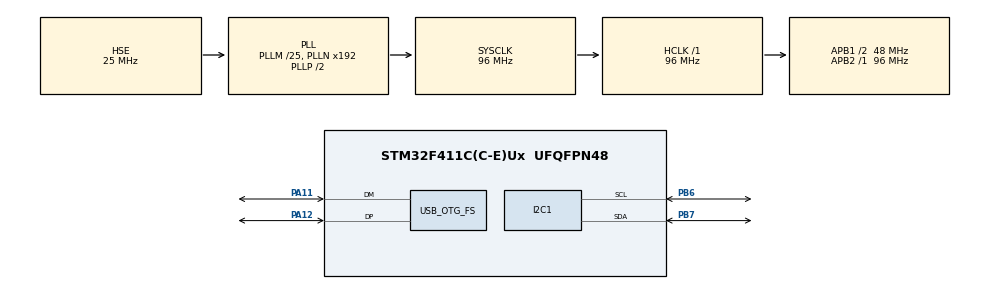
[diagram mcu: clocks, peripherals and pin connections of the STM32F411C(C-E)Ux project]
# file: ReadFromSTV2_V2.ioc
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Dma.I2C1_RX.0.Direction=DMA_PERIPH_TO_MEMORY
Dma.I2C1_RX.0.FIFOMode=DMA_FIFOMODE_DISABLE
Dma.I2C1_RX.0.Instance=DMA1_Stream0
Dma.I2C1_RX.0.MemDataAlignment=DMA_MDATAALIGN_BYTE
Dma.I2C1_RX.0.MemInc=DMA_MINC_ENABLE
Dma.I2C1_RX.0.Mode=DMA_NORMAL
Dma.I2C1_RX.0.PeriphDataAlignment=DMA_PDATAALIGN_BYTE
Dma.I2C1_RX.0.PeriphInc=DMA_PINC_DISABLE
Dma.I2C1_RX.0.Priority=DMA_PRIORITY_LOW
Dma.Request0=I2C1_RX
Mcu.Family=STM32F4
Mcu.Name=STM32F411C(C-E)Ux
Mcu.Package=UFQFPN48
NVIC.DMA1_Stream0_IRQn=true\:0\:0\:false\:false\:true\:false\:true\:true
NVIC.I2C1_ER_IRQn=true\:0\:0\:false\:false\:true\:true\:true\:true
NVIC.I2C1_EV_IRQn=true\:0\:0\:false\:false\:true\:true\:true\:true
NVIC.OTG_FS_IRQn=true\:0\:0\:false\:false\:true\:false\:true\:true
NVIC.PriorityGroup=NVIC_PRIORITYGROUP_4
NVIC.TIM2_IRQn=true\:0\:0\:false\:false\:true\:true\:true\:true
PA11.Mode=Device_Only
PA11.Signal=USB_OTG_FS_DM
PA12.Mode=Device_Only
PA12.Signal=USB_OTG_FS_DP
PB6.Mode=I2C
PB6.Signal=I2C1_SCL
PB7.Mode=I2C
PB7.Signal=I2C1_SDA
PH0\ -\ OSC_IN.Mode=HSE-External-Oscillator
PH0\ -\ OSC_IN.Signal=RCC_OSC_IN
PH1\ -\ OSC_OUT.Mode=HSE-External-Oscillator
PH1\ -\ OSC_OUT.Signal=RCC_OSC_OUT
ProjectManager.HeapSize=0x200
ProjectManager.StackSize=0x400
ProjectManager.TargetToolchain=STM32CubeIDE
RCC.48MHZClocksFreq_Value=48000000
RCC.AHBFreq_Value=96000000
RCC.APB1CLKDivider=RCC_HCLK_DIV2
RCC.APB1Freq_Value=48000000
RCC.APB1TimFreq_Value=96000000
RCC.APB2Freq_Value=96000000
RCC.APB2TimFreq_Value=96000000
RCC.CortexFreq_Value=96000000
RCC.HCLKFreq_Value=96000000
RCC.HSE_VALUE=25000000
RCC.HSI_VALUE=16000000
RCC.LSE_VALUE=32768
RCC.PLLM=25
RCC.SYSCLKFreq_VALUE=96000000
RCC.SYSCLKSource=RCC_SYSCLKSOURCE_PLLCLK
RCC.VCOOutputFreq_Value=192000000
TIM2.Period=999
TIM2.Prescaler=95
USB_DEVICE.CLASS_NAME_FS=HID
USB_DEVICE.VirtualMode=Hid
USB_DEVICE.VirtualModeFS=Hid_FS
USB_OTG_FS.VirtualMode=Device_Only
VP_TIM2_VS_ClockSourceINT.Mode=Internal
VP_USB_DEVICE_VS_USB_DEVICE_HID_FS.Mode=HID_FS
board=custom

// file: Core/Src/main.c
/* USER CODE BEGIN Header */
/**
  ******************************************************************************
  * @file           : main.c
  * @brief          : Main program body
  ******************************************************************************
  * @attention
  *
  * Copyright (c) 2026 STMicroelectronics.
  * All rights reserved.
  *
  * This software is licensed under terms that can be found in the LICENSE file
  * in the root directory of this software component.
  * If no LICENSE file comes with this software, it is provided AS-IS.
  *
  ******************************************************************************
  */
/* USER CODE END Header */
#include "main.h"
#include "usb_device.h"

I2C_HandleTypeDef hi2c1;
DMA_HandleTypeDef hdma_i2c1_rx;

TIM_HandleTypeDef htim2;

/* USER CODE BEGIN PV */
#define AS5600_ADDR (0x36 << 1)
static uint8_t as5600_buf[2];
volatile uint16_t raw_angle;
/* USER CODE END PV */

void SystemClock_Config(void);
static void MX_GPIO_Init(void);
static void MX_DMA_Init(void);
static void MX_I2C1_Init(void);
static void MX_TIM2_Init(void);

int main(void)
{

  /* MCU Configuration--------------------------------------------------------*/

  /* Reset of all peripherals, Initializes the Flash interface and the Systick. */
  HAL_Init();

  /* Configure the system clock */
  SystemClock_Config();

  /* Initialize all configured peripherals */
  MX_GPIO_Init();
  MX_DMA_Init();
  MX_I2C1_Init();
  MX_TIM2_Init();
  MX_USB_DEVICE_Init();
  /* USER CODE BEGIN 2 */
  HAL_TIM_Base_Start_IT(&htim2);
  /* USER CODE END 2 */

  /* Infinite loop */
  while (1)
  {

  }
}

void SystemClock_Config(void)
{
  RCC_OscInitTypeDef RCC_OscInitStruct = {0};
  RCC_ClkInitTypeDef RCC_ClkInitStruct = {0};

  /** Configure the main internal regulator output voltage
  */
  __HAL_RCC_PWR_CLK_ENABLE();
  __HAL_PWR_VOLTAGESCALING_CONFIG(PWR_REGULATOR_VOLTAGE_SCALE1);

  /** Initializes the RCC Oscillators according to the specified parameters
  * in the RCC_OscInitTypeDef structure.
  */
  RCC_OscInitStruct.OscillatorType = RCC_OSCILLATORTYPE_HSE;
  RCC_OscInitStruct.HSEState = RCC_HSE_ON;
  RCC_OscInitStruct.PLL.PLLState = RCC_PLL_ON;
  RCC_OscInitStruct.PLL.PLLSource = RCC_PLLSOURCE_HSE;
  RCC_OscInitStruct.PLL.PLLM = 25;
  RCC_OscInitStruct.PLL.PLLN = 192;
  RCC_OscInitStruct.PLL.PLLP = RCC_PLLP_DIV2;
  RCC_OscInitStruct.PLL.PLLQ = 4;
  if (HAL_RCC_OscConfig(&RCC_OscInitStruct) != HAL_OK)
  {
    Error_Handler();
  }

  /** Initializes the CPU, AHB and APB buses clocks
  */
  RCC_ClkInitStruct.ClockType = RCC_CLOCKTYPE_HCLK|RCC_CLOCKTYPE_SYSCLK
                              |RCC_CLOCKTYPE_PCLK1|RCC_CLOCKTYPE_PCLK2;
  RCC_ClkInitStruct.SYSCLKSource = RCC_SYSCLKSOURCE_PLLCLK;
  RCC_ClkInitStruct.AHBCLKDivider = RCC_SYSCLK_DIV1;
  RCC_ClkInitStruct.APB1CLKDivider = RCC_HCLK_DIV2;
  RCC_ClkInitStruct.APB2CLKDivider = RCC_HCLK_DIV1;

  if (HAL_RCC_ClockConfig(&RCC_ClkInitStruct, FLASH_LATENCY_3) != HAL_OK)
  {
    Error_Handler();
  }
}

static void MX_I2C1_Init(void)
{

  hi2c1.Instance = I2C1;
  hi2c1.Init.ClockSpeed = 100000;
  hi2c1.Init.DutyCycle = I2C_DUTYCYCLE_2;
  hi2c1.Init.OwnAddress1 = 0;
  hi2c1.Init.AddressingMode = I2C_ADDRESSINGMODE_7BIT;
  hi2c1.Init.DualAddressMode = I2C_DUALADDRESS_DISABLE;
  hi2c1.Init.OwnAddress2 = 0;
  hi2c1.Init.GeneralCallMode = I2C_GENERALCALL_DISABLE;
  hi2c1.Init.NoStretchMode = I2C_NOSTRETCH_DISABLE;
  if (HAL_I2C_Init(&hi2c1) != HAL_OK)
  {
    Error_Handler();
  }

}

static void MX_TIM2_Init(void)
{

  TIM_ClockConfigTypeDef sClockSourceConfig = {0};
  TIM_MasterConfigTypeDef sMasterConfig = {0};

  htim2.Instance = TIM2;
  htim2.Init.Prescaler = 95;
  htim2.Init.CounterMode = TIM_COUNTERMODE_UP;
  htim2.Init.Period = 999;
  htim2.Init.ClockDivision = TIM_CLOCKDIVISION_DIV1;
  htim2.Init.AutoReloadPreload = TIM_AUTORELOAD_PRELOAD_DISABLE;
  if (HAL_TIM_Base_Init(&htim2) != HAL_OK)
  {
    Error_Handler();
  }
  sClockSourceConfig.ClockSource = TIM_CLOCKSOURCE_INTERNAL;
  if (HAL_TIM_ConfigClockSource(&htim2, &sClockSourceConfig) != HAL_OK)
  {
    Error_Handler();
  }
  sMasterConfig.MasterOutputTrigger = TIM_TRGO_RESET;
  sMasterConfig.MasterSlaveMode = TIM_MASTERSLAVEMODE_DISABLE;
  if (HAL_TIMEx_MasterConfigSynchronization(&htim2, &sMasterConfig) != HAL_OK)
  {
    Error_Handler();
  }

}

static void MX_DMA_Init(void)
{

  /* DMA controller clock enable */
  __HAL_RCC_DMA1_CLK_ENABLE();

  /* DMA interrupt init */
  /* DMA1_Stream0_IRQn interrupt configuration */
  HAL_NVIC_SetPriority(DMA1_Stream0_IRQn, 0, 0);
  HAL_NVIC_EnableIRQ(DMA1_Stream0_IRQn);

}

static void MX_GPIO_Init(void)
{

  /* GPIO Ports Clock Enable */
  __HAL_RCC_GPIOH_CLK_ENABLE();
  __HAL_RCC_GPIOA_CLK_ENABLE();
  __HAL_RCC_GPIOB_CLK_ENABLE();

}

/* USER CODE BEGIN 4 */
	void HAL_TIM_PeriodElapsedCallback(TIM_HandleTypeDef *htim2) {
		if (htim->Instance == TIM2) {
			if (hi2c1.State == HAL_I2C_STATE_READY) {
				HAL_I2C_Mem_Read_DMA(&hi2c1, AS5600_ADDR, 0x0C, I2C_MEMADD_SIZE_8BIT, as5600_buf, 2);
			}
		}
	}
	void HAL_I2C_MemRxCpltCallback(I2C_HandleTypeDef *hi2c) {
		if (hi2c->Instance == I2C1) {
			raw_angle = ((as5600_buf[0] << 8) | as5600_buf[1]) & 0x0FFF;
		}
	}
/* USER CODE END 4 */

void Error_Handler(void)
{
  __disable_irq();
  while (1)
  {
  }
}
